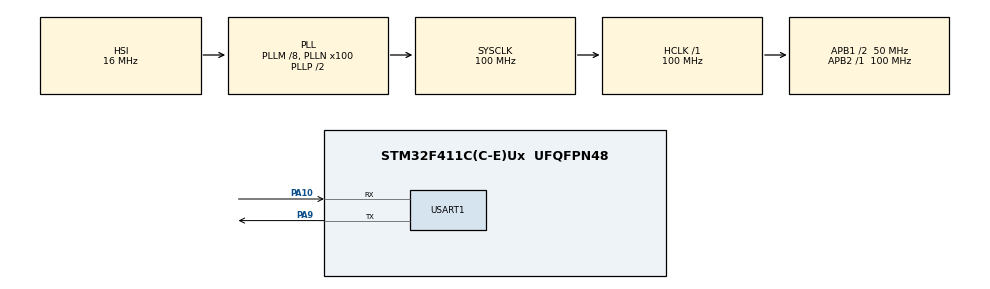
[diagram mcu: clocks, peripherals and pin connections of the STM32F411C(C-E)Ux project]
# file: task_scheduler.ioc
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FREERTOS.Tasks01=SensorReaderTask,24,128,StartSensorReaderTask,Default,NULL,Dynamic,NULL,NULL;EventTriggerTask,8,128,StartEventTriggerTask,Default,NULL,Dynamic,NULL,NULL;MaintenanceTask,56,128,StartMaintenanceTask,Default,NULL,Dynamic,NULL,NULL
FREERTOS.configTOTAL_HEAP_SIZE=15360
FREERTOS.configMAX_PRIORITIES=56
FREERTOS.configTIMER_TASK_STACK_DEPTH=256
FREERTOS.configMINIMAL_STACK_SIZE=128
FREERTOS.configUSE_PORT_OPTIMISED_TASK_SELECTION=0
Mcu.Family=STM32F4
Mcu.Name=STM32F411C(C-E)Ux
Mcu.Package=UFQFPN48
NVIC.PriorityGroup=NVIC_PRIORITYGROUP_4
NVIC.TIM1_TRG_COM_TIM11_IRQn=true\:5\:0\:false\:false\:true\:false\:true\:false
PA10.Mode=Asynchronous
PA10.Signal=USART1_RX
PA9.Mode=Asynchronous
PA9.Signal=USART1_TX
ProjectManager.HeapSize=0x200
ProjectManager.StackSize=0x400
ProjectManager.TargetToolchain=STM32CubeIDE
RCC.AHBFreq_Value=100000000
RCC.APB1CLKDivider=RCC_HCLK_DIV2
RCC.APB1Freq_Value=50000000
RCC.APB1TimFreq_Value=100000000
RCC.APB2Freq_Value=100000000
RCC.APB2TimFreq_Value=100000000
RCC.CortexFreq_Value=100000000
RCC.HCLKFreq_Value=100000000
RCC.HSE_VALUE=25000000
RCC.HSI_VALUE=16000000
RCC.LSE_VALUE=32768
RCC.PLLM=8
RCC.PLLN=100
RCC.PLLP=RCC_PLLP_DIV2
RCC.PLLSourceVirtual=RCC_PLLSOURCE_HSI
RCC.SYSCLKFreq_VALUE=100000000
RCC.SYSCLKSource=RCC_SYSCLKSOURCE_PLLCLK
RCC.VCOOutputFreq_Value=200000000
USART1.VirtualMode=VM_ASYNC
VP_FREERTOS_VS_CMSIS_V2.Mode=CMSIS_V2
VP_SYS_VS_tim11.Mode=TIM11
board=custom

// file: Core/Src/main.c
/* USER CODE BEGIN Header */
/**
  ******************************************************************************
  * @file           : main.c
  * @brief          : Main program body
  ******************************************************************************
  * @attention
  *
  * Copyright (c) 2026 STMicroelectronics.
  * All rights reserved.
  *
  * This software is licensed under terms that can be found in the LICENSE file
  * in the root directory of this software component.
  * If no LICENSE file comes with this software, it is provided AS-IS.
  *
  ******************************************************************************
  */
/* USER CODE END Header */
#include "main.h"
#include "cmsis_os.h"

/* USER CODE BEGIN Includes */
#include <stdio.h>
/* USER CODE END Includes */

UART_HandleTypeDef huart1;

/* Definitions for SensorReaderTask */
osThreadId_t SensorReaderTaskHandle;
const osThreadAttr_t SensorReaderTask_attributes = {
  .name = "SensorReader",
  .stack_size = 128 * 4,
  .priority = (osPriority_t) osPriorityNormal,
};
/* Definitions for EventTriggerTask */
osThreadId_t EventTriggerTaskHandle;
const osThreadAttr_t EventTriggerTask_attributes = {
  .name = "EventTrigger",
  .stack_size = 128 * 4,
  .priority = (osPriority_t) osPriorityLow,
};
/* Definitions for WorkerTask (created dynamically by EventTriggerTask) */
const osThreadAttr_t WorkerTask_attributes = {
  .name = "Worker",
  .stack_size = 128 * 4,
  .priority = (osPriority_t) osPriorityHigh,
};
/* Definitions for MaintenanceTask */
osThreadId_t MaintenanceTaskHandle;
const osThreadAttr_t MaintenanceTask_attributes = {
  .name = "Maintenance",
  .stack_size = 128 * 4,
  .priority = (osPriority_t) osPriorityRealtime,
};

void SystemClock_Config(void);
static void MX_GPIO_Init(void);
static void MX_USART1_UART_Init(void);
void StartSensorReaderTask(void *argument);
void StartEventTriggerTask(void *argument);
void StartWorkerTask(void *argument);
void StartMaintenanceTask(void *argument);

/* USER CODE BEGIN 0 */
// Перенаправлення printf на USART1 (блокуючий режим, для простих навчальних задач цього достатньо).
int _write(int file, char *ptr, int len)
{
  HAL_UART_Transmit(&huart1, (uint8_t *)ptr, len, HAL_MAX_DELAY);
  return len;
}
/* USER CODE END 0 */

int main(void)
{

  /* MCU Configuration--------------------------------------------------------*/

  /* Reset of all peripherals, Initializes the Flash interface and the Systick. */
  HAL_Init();

  /* Configure the system clock */
  SystemClock_Config();

  /* Initialize all configured peripherals */
  MX_GPIO_Init();
  MX_USART1_UART_Init();

  /* Init scheduler */
  osKernelInitialize();

  /* Create the thread(s) */
  /* creation of SensorReaderTask */
  SensorReaderTaskHandle = osThreadNew(StartSensorReaderTask, NULL, &SensorReaderTask_attributes);

  /* creation of EventTriggerTask */
  EventTriggerTaskHandle = osThreadNew(StartEventTriggerTask, NULL, &EventTriggerTask_attributes);

  /* creation of MaintenanceTask */
  MaintenanceTaskHandle = osThreadNew(StartMaintenanceTask, NULL, &MaintenanceTask_attributes);

  /* NOTE: WorkerTask is NOT created here. It is created dynamically at
     runtime by EventTriggerTask whenever the simulated event fires, and it
     deletes itself (osThreadExit) once its job is done. */

  /* Start scheduler */
  osKernelStart();

  /* We should never get here as control is now taken by the scheduler */

  /* Infinite loop */
  while (1)
  {

  }
}

void SystemClock_Config(void)
{
  RCC_OscInitTypeDef RCC_OscInitStruct = {0};
  RCC_ClkInitTypeDef RCC_ClkInitStruct = {0};

  /** Configure the main internal regulator output voltage
  */
  __HAL_RCC_PWR_CLK_ENABLE();
  __HAL_PWR_VOLTAGESCALING_CONFIG(PWR_REGULATOR_VOLTAGE_SCALE1);

  /** Initializes the RCC Oscillators according to the specified parameters
  * in the RCC_OscInitTypeDef structure.
  */
  RCC_OscInitStruct.OscillatorType = RCC_OSCILLATORTYPE_HSI;
  RCC_OscInitStruct.HSIState = RCC_HSI_ON;
  RCC_OscInitStruct.HSICalibrationValue = RCC_HSICALIBRATION_DEFAULT;
  RCC_OscInitStruct.PLL.PLLState = RCC_PLL_ON;
  RCC_OscInitStruct.PLL.PLLSource = RCC_PLLSOURCE_HSI;
  RCC_OscInitStruct.PLL.PLLM = 8;
  RCC_OscInitStruct.PLL.PLLN = 100;
  RCC_OscInitStruct.PLL.PLLP = RCC_PLLP_DIV2;
  RCC_OscInitStruct.PLL.PLLQ = 4;
  if (HAL_RCC_OscConfig(&RCC_OscInitStruct) != HAL_OK)
  {
    Error_Handler();
  }

  /** Initializes the CPU, AHB and APB buses clocks
  */
  RCC_ClkInitStruct.ClockType = RCC_CLOCKTYPE_HCLK|RCC_CLOCKTYPE_SYSCLK
                              |RCC_CLOCKTYPE_PCLK1|RCC_CLOCKTYPE_PCLK2;
  RCC_ClkInitStruct.SYSCLKSource = RCC_SYSCLKSOURCE_PLLCLK;
  RCC_ClkInitStruct.AHBCLKDivider = RCC_SYSCLK_DIV1;
  RCC_ClkInitStruct.APB1CLKDivider = RCC_HCLK_DIV2;
  RCC_ClkInitStruct.APB2CLKDivider = RCC_HCLK_DIV1;

  if (HAL_RCC_ClockConfig(&RCC_ClkInitStruct, FLASH_LATENCY_3) != HAL_OK)
  {
    Error_Handler();
  }
}

static void MX_USART1_UART_Init(void)
{

  huart1.Instance = USART1;
  huart1.Init.BaudRate = 115200;
  huart1.Init.WordLength = UART_WORDLENGTH_8B;
  huart1.Init.StopBits = UART_STOPBITS_1;
  huart1.Init.Parity = UART_PARITY_NONE;
  huart1.Init.Mode = UART_MODE_TX_RX;
  huart1.Init.HwFlowCtl = UART_HWCONTROL_NONE;
  huart1.Init.OverSampling = UART_OVERSAMPLING_16;
  if (HAL_UART_Init(&huart1) != HAL_OK)
  {
    Error_Handler();
  }

}

static void MX_GPIO_Init(void)
{

  /* GPIO Ports Clock Enable */
  __HAL_RCC_GPIOH_CLK_ENABLE();
  __HAL_RCC_GPIOA_CLK_ENABLE();

}

/* USER CODE BEGIN Header_StartSensorReaderTask */
/**
  * @brief  Function implementing the SensorReaderTask thread.
  *         Imitates polling a sensor with a strictly periodic 500 ms rate.
  *         osDelayUntil (not plain osDelay) is used on purpose: it schedules
  *         the next wake-up relative to the *previous* wake-up time, so the
  *         period stays exactly 500 ms regardless of how long the task body
  *         itself takes to run - a plain osDelay(500) would instead measure
  *         500 ms from "when the task finished", letting jitter accumulate.
  * @param  argument: Not used
  * @retval None
  */
/* USER CODE END Header_StartSensorReaderTask */
void StartSensorReaderTask(void *argument)
{
  /* USER CODE BEGIN StartSensorReaderTask */
  uint32_t lastWakeTime = osKernelGetTickCount();
  const uint32_t periodTicks = 500;

  /* Infinite loop */
  for(;;)
  {
    printf("[Sensor] Data read...\r\n");

    lastWakeTime += periodTicks;
    osDelayUntil(lastWakeTime);
  }
  /* USER CODE END StartSensorReaderTask */
}

/* USER CODE BEGIN Header_StartEventTriggerTask */
/**
  * @brief Function implementing the EventTriggerTask thread.
  *        Imitates an unpredictable external event: sleeps for 3 s, then
  *        dynamically spawns a WorkerTask to handle the "event" and goes
  *        back to sleep.
  * @param argument: Not used
  * @retval None
  */
/* USER CODE END Header_StartEventTriggerTask */
void StartEventTriggerTask(void *argument)
{
  /* USER CODE BEGIN StartEventTriggerTask */
  /* Infinite loop */
  for(;;)
  {
    osDelay(3000);

    osThreadNew(StartWorkerTask, NULL, &WorkerTask_attributes);
  }
  /* USER CODE END StartEventTriggerTask */
}

/* USER CODE BEGIN Header_StartWorkerTask */
/**
  * @brief Function implementing the WorkerTask thread.
  *        Created on demand by EventTriggerTask. Does one unit of work and
  *        then MUST terminate itself with osThreadExit() (CMSIS-RTOS2
  *        equivalent of vTaskDelete(NULL)) - simply returning/falling off
  *        the end of the function is undefined behaviour for a FreeRTOS
  *        task and is not allowed.
  * @param argument: Not used
  * @retval None
  */
/* USER CODE END Header_StartWorkerTask */
void StartWorkerTask(void *argument)
{
  /* USER CODE BEGIN StartWorkerTask */
  printf("[Worker] Processing event...\r\n");

  osThreadExit();
  /* USER CODE END StartWorkerTask */
}

/* USER CODE BEGIN Header_StartMaintenanceTask */
/**
  * @brief Function implementing the MaintenanceTask thread.
  *        Highest (Realtime) priority. Once every 10 s it puts the device
  *        into a simulated service mode: pauses SensorReaderTask, waits 2 s,
  *        then resumes it.
  * @param argument: Not used
  * @retval None
  */
/* USER CODE END Header_StartMaintenanceTask */
void StartMaintenanceTask(void *argument)
{
  /* USER CODE BEGIN StartMaintenanceTask */
  /* Infinite loop */
  for(;;)
  {
    osDelay(10000);

    osThreadSuspend(SensorReaderTaskHandle);

    printf("[Maintenance] System paused for 2 seconds.\r\n");
    osDelay(2000);

    osThreadResume(SensorReaderTaskHandle);
  }
  /* USER CODE END StartMaintenanceTask */
}

void Error_Handler(void)
{
  __disable_irq();
  while (1)
  {
  }
}
